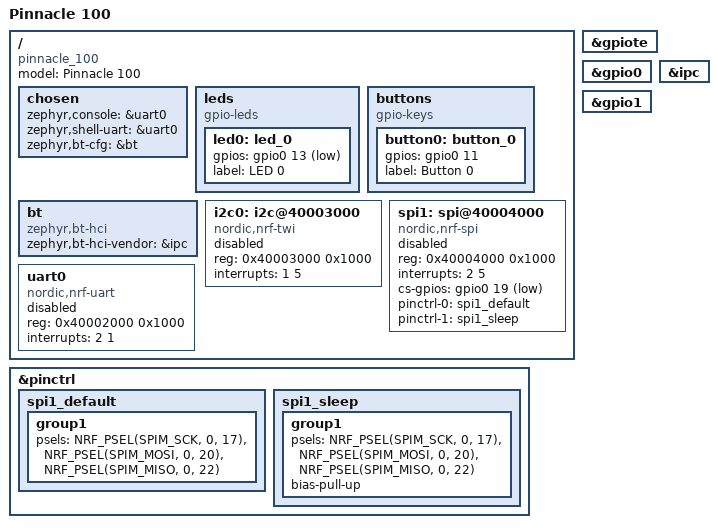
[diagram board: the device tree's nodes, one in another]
/*
 * Pinnacle 100 Board Device Tree Source Include
 */

#include <nordic/nrf52840_qiaa.dtsi>

/ {
    model = "Pinnacle 100";
    compatible = "pinnacle_100", "nordic,nrf52840-qiaa";

    chosen {
        zephyr,console = &uart0;
        zephyr,shell-uart = &uart0;
        zephyr,bt-cfg = &bt;
    };

    leds {
        compatible = "gpio-leds";
        led0: led_0 {
            gpios = <&gpio0 13 GPIO_ACTIVE_LOW>;
            label = "LED 0";
        };
    };

    buttons {
        compatible = "gpio-keys";
        button0: button_0 {
            gpios = <&gpio0 11 GPIO_PULL_UP>;
            label = "Button 0";
        };
    };

    bt {
        compatible = "zephyr,bt-hci";
        zephyr,bt-hci-vendor = "&ipc";
    };

    i2c0: i2c@40003000 {
        compatible = "nordic,nrf-twi";
        reg = <0x40003000 0x1000>;
        interrupts = <1 5>;
        status = "disabled";
    };

    spi1: spi@40004000 {
        compatible = "nordic,nrf-spi";
        reg = <0x40004000 0x1000>;
        interrupts = <2 5>;
        status = "disabled";
        cs-gpios = <&gpio0 19 GPIO_ACTIVE_LOW>;
        pinctrl-0 = <&spi1_default>;
        pinctrl-1 = <&spi1_sleep>;
        pinctrl-names = "default", "sleep";
    };

    uart0: uart0 {
        compatible = "nordic,nrf-uart";
        reg = <0x40002000 0x1000>;
        interrupts = <2 1>;
        status = "disabled";
    };
};

&gpiote {
    status = "okay";
};

&gpio0 {
    status = "okay";
};

&gpio1 {
    status = "okay";
};

&pinctrl {
    spi1_default: spi1_default {
        group1 {
            psels = <NRF_PSEL(SPIM_SCK, 0, 17)>,
                    <NRF_PSEL(SPIM_MOSI, 0, 20)>,
                    <NRF_PSEL(SPIM_MISO, 0, 22)>;
        };
    };

    spi1_sleep: spi1_sleep {
        group1 {
            psels = <NRF_PSEL(SPIM_SCK, 0, 17)>,
                    <NRF_PSEL(SPIM_MOSI, 0, 20)>,
                    <NRF_PSEL(SPIM_MISO, 0, 22)>;
            bias-pull-up;
        };
    };
};

&ipc {
    status = "okay";
};
